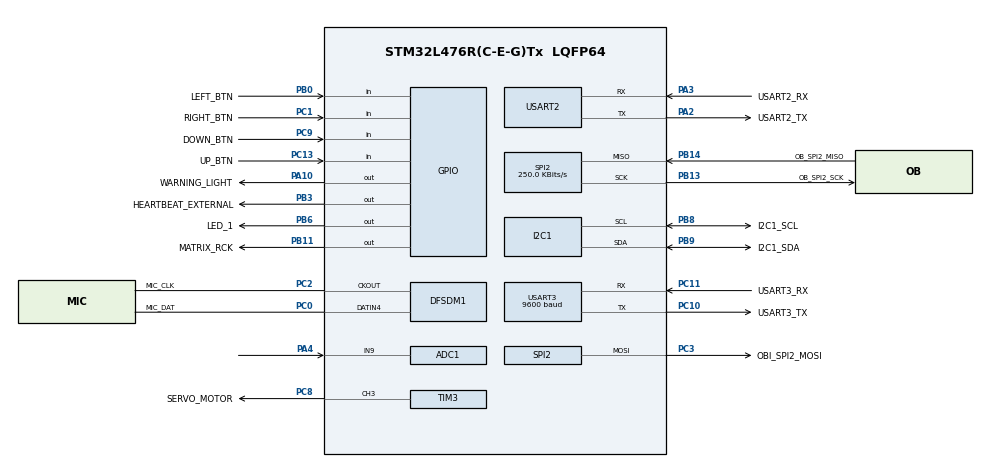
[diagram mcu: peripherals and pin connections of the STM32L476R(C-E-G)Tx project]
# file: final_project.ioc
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ADC1.Channel-0\#ChannelRegularConversion=ADC_CHANNEL_9
ADC1.NbrOfConversionFlag=1
ADC1.OffsetNumber-0\#ChannelRegularConversion=ADC_OFFSET_NONE
ADC1.Rank-0\#ChannelRegularConversion=1
ADC1.SamplingTime-0\#ChannelRegularConversion=ADC_SAMPLETIME_12CYCLES_5
ADC1.master=1
DFSDM1.Divider=2
DFSDM1.DmaMode_reg_FIL0=ENABLE
DFSDM1.DmaMode_reg_FIL1=ENABLE
DFSDM1.FastMode_reg_FIL0=ENABLE
DFSDM1.FastMode_reg_FIL1=ENABLE
DFSDM1.Filter_regChannel_FIL0=DFSDM_CHANNEL_4
DFSDM1.Filter_regChannel_FIL1=DFSDM_CHANNEL_3
DFSDM1.Fosr_FIL0=38
DFSDM1.Fosr_FIL1=38
DFSDM1.Iosr_FIL0=4
DFSDM1.Iosr_FIL1=4
DFSDM1.RightBitShift_CH3=0x08
DFSDM1.RightBitShift_CH4=0x08
DFSDM1.SincOrder_FIL0=DFSDM_FILTER_SINC4_ORDER
DFSDM1.SincOrder_FIL1=DFSDM_FILTER_SINC4_ORDER
DFSDM1.Type_spi_CH4=DFSDM_CHANNEL_SPI_FALLING
Dma.DFSDM1_FLT0.0.Direction=DMA_PERIPH_TO_MEMORY
Dma.DFSDM1_FLT0.0.Instance=DMA1_Channel4
Dma.DFSDM1_FLT0.0.MemDataAlignment=DMA_MDATAALIGN_WORD
Dma.DFSDM1_FLT0.0.MemInc=DMA_MINC_ENABLE
Dma.DFSDM1_FLT0.0.Mode=DMA_CIRCULAR
Dma.DFSDM1_FLT0.0.PeriphDataAlignment=DMA_PDATAALIGN_WORD
Dma.DFSDM1_FLT0.0.PeriphInc=DMA_PINC_DISABLE
Dma.DFSDM1_FLT0.0.Priority=DMA_PRIORITY_LOW
Dma.DFSDM1_FLT1.1.Direction=DMA_PERIPH_TO_MEMORY
Dma.DFSDM1_FLT1.1.Instance=DMA1_Channel5
Dma.DFSDM1_FLT1.1.MemDataAlignment=DMA_MDATAALIGN_WORD
Dma.DFSDM1_FLT1.1.MemInc=DMA_MINC_ENABLE
Dma.DFSDM1_FLT1.1.Mode=DMA_CIRCULAR
Dma.DFSDM1_FLT1.1.PeriphDataAlignment=DMA_PDATAALIGN_WORD
Dma.DFSDM1_FLT1.1.PeriphInc=DMA_PINC_DISABLE
Dma.DFSDM1_FLT1.1.Priority=DMA_PRIORITY_LOW
Dma.Request0=DFSDM1_FLT0
Dma.Request1=DFSDM1_FLT1
FREERTOS.Tasks01=defaultTask,24,128,StartDefaultTask,Default,NULL,Dynamic,NULL,NULL
I2C1.Timing=0x00100D14
Mcu.Family=STM32L4
Mcu.Name=STM32L476R(C-E-G)Tx
Mcu.Package=LQFP64
NVIC.DMA1_Channel4_IRQn=true\:5\:0\:false\:false\:true\:true\:false\:true\:true
NVIC.DMA1_Channel5_IRQn=true\:5\:0\:false\:false\:true\:true\:false\:true\:true
NVIC.PriorityGroup=NVIC_PRIORITYGROUP_4
PA10.GPIO_Label=WARNING_LIGHT
PA10.Signal=GPIO_Output
PA2.GPIO_Label=USART2_TX
PA2.Mode=Asynchronous
PA2.Signal=USART2_TX
PA3.GPIO_Label=USART2_RX
PA3.Mode=Asynchronous
PA3.Signal=USART2_RX
PA4.Signal=ADCx_IN9
PB0.GPIO_Label=LEFT_BTN
PB0.Signal=GPIO_Input
PB11.GPIO_Label=MATRIX_RCK
PB11.Signal=GPIO_Output
PB13.GPIO_Label=OB_SPI2_SCK
PB13.Mode=Full_Duplex_Master
PB13.Signal=SPI2_SCK
PB14.GPIO_Label=OB_SPI2_MISO
PB14.Mode=Full_Duplex_Master
PB14.Signal=SPI2_MISO
PB3\ (JTDO-TRACESWO).GPIO_Label=HEARTBEAT_EXTERNAL
PB3\ (JTDO-TRACESWO).Signal=GPIO_Output
PB6.GPIO_Label=LED_1
PB6.Signal=GPIO_Output
PB8.GPIO_Label=I2C1_SCL
PB8.Mode=I2C
PB8.Signal=I2C1_SCL
PB9.GPIO_Label=I2C1_SDA
PB9.Mode=I2C
PB9.Signal=I2C1_SDA
PC0.GPIO_Label=MIC_DAT
PC0.Signal=S_DATAIN4DFSDM1
PC1.GPIO_Label=RIGHT_BTN
PC1.Signal=GPIO_Input
PC10.GPIO_Label=USART3_TX
PC10.Mode=Asynchronous
PC10.Signal=USART3_TX
PC11.GPIO_Label=USART3_RX
PC11.Mode=Asynchronous
PC11.Signal=USART3_RX
PC13.GPIO_Label=UP_BTN
PC13.Signal=GPIO_Input
PC2.GPIO_Label=MIC_CLK
PC2.Signal=S_CKOUTDFSDM1
PC3.GPIO_Label=OBI_SPI2_MOSI
PC3.Mode=Full_Duplex_Master
PC3.Signal=SPI2_MOSI
PC8.GPIO_Label=SERVO_MOTOR
PC8.Signal=S_TIM3_CH3
PC9.GPIO_Label=DOWN_BTN
PC9.Signal=GPIO_Input
ProjectManager.HeapSize=0x200
ProjectManager.StackSize=0x400
ProjectManager.TargetToolchain=CMake
RCC.ADCFreq_Value=32000000
RCC.HSE_VALUE=8000000
RCC.HSI_VALUE=16000000
RCC.LSE_VALUE=32768
RCC.MSI_VALUE=4000000
RCC.PLLSAI1N=16
RCC.USBFreq_Value=32000000
RCC.VCOOutputFreq_Value=32000000
SH.ADCx_IN9.0=ADC1_IN9,IN9-Single-Ended
SH.S_CKOUTDFSDM1.0=DFSDM1_CKOUT,PDM_SPI_input_from_ch4_and_internal_clock
SH.S_CKOUTDFSDM1.1=DFSDM1_CKOUT,PDM_SPI_Input_from_ch34_and_Internal_Clock
SH.S_DATAIN4DFSDM1.0=DFSDM1_DATIN4,PDM_SPI_input_from_ch4_and_internal_clock
SH.S_DATAIN4DFSDM1.1=DFSDM1_DATIN4,PDM_SPI_Input_from_ch34_and_Internal_Clock
SH.S_TIM3_CH3.0=TIM3_CH3,PWM Generation3 CH3
SPI2.BaudRatePrescaler=SPI_BAUDRATEPRESCALER_16
SPI2.CalculateBaudRate=250.0 KBits/s
SPI2.DataSize=SPI_DATASIZE_8BIT
SPI2.Direction=SPI_DIRECTION_2LINES
SPI2.Mode=SPI_MODE_MASTER
SPI2.VirtualType=VM_MASTER
TIM3.Channel-PWM\ Generation3\ CH3=TIM_CHANNEL_3
TIM3.Period=19999
TIM3.Prescaler=3
USART2.VirtualMode-Asynchronous=VM_ASYNC
USART3.BaudRate=9600
USART3.VirtualMode-Asynchronous=VM_ASYNC
VP_FREERTOS_VS_CMSIS_V2.Mode=CMSIS_V2
board=custom

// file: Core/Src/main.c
/* USER CODE BEGIN Header */
/**
  ******************************************************************************
  * @file           : main.c
  * @brief          : Main program body
  ******************************************************************************
  * @attention
  *
  * Copyright (c) 2026 STMicroelectronics.
  * All rights reserved.
  *
  * This software is licensed under terms that can be found in the LICENSE file
  * in the root directory of this software component.
  * If no LICENSE file comes with this software, it is provided AS-IS.
  *
  ******************************************************************************
  */
/* USER CODE END Header */
#include "main.h"
#include "cmsis_os.h"

/* USER CODE BEGIN Includes */
#include "app.h"
/* USER CODE END Includes */

ADC_HandleTypeDef hadc1;

DFSDM_Filter_HandleTypeDef hdfsdm1_filter0;
DFSDM_Filter_HandleTypeDef hdfsdm1_filter1;
DFSDM_Channel_HandleTypeDef hdfsdm1_channel3;
DFSDM_Channel_HandleTypeDef hdfsdm1_channel4;
DMA_HandleTypeDef hdma_dfsdm1_flt0;
DMA_HandleTypeDef hdma_dfsdm1_flt1;

I2C_HandleTypeDef hi2c1;

SPI_HandleTypeDef hspi2;

TIM_HandleTypeDef htim3;

UART_HandleTypeDef huart2;
UART_HandleTypeDef huart3;

/* Definitions for defaultTask */
osThreadId_t defaultTaskHandle;
const osThreadAttr_t defaultTask_attributes = {
  .name = "defaultTask",
  .stack_size = 128 * 4,
  .priority = (osPriority_t) osPriorityNormal,
};

void SystemClock_Config(void);
static void MX_GPIO_Init(void);
static void MX_DMA_Init(void);
static void MX_ADC1_Init(void);
static void MX_DFSDM1_Init(void);
static void MX_I2C1_Init(void);
static void MX_SPI2_Init(void);
static void MX_TIM3_Init(void);
static void MX_USART2_UART_Init(void);
static void MX_USART3_UART_Init(void);
void StartDefaultTask(void *argument);

int main(void)
{

  /* MCU Configuration--------------------------------------------------------*/

  /* Reset of all peripherals, Initializes the Flash interface and the Systick. */
  HAL_Init();

  /* Configure the system clock */
  SystemClock_Config();

  /* Initialize all configured peripherals */
  MX_GPIO_Init();
  MX_DMA_Init();
  MX_ADC1_Init();
  MX_DFSDM1_Init();
  MX_I2C1_Init();
  MX_SPI2_Init();
  MX_TIM3_Init();
  MX_USART2_UART_Init();
  MX_USART3_UART_Init();
  /* USER CODE BEGIN 2 */
   // start freeRTOS app
    int err = app_main();
  UNUSED(err);

  Error_Handler(); // If app_main returns, there was an error. Handle it.

  // HD44780_Init(2); // Initialize LCD with 2 rows
  //  HD44780_Clear(); // Clear the display
  //  HD44780_Backlight(); // Turn on the backlight
  //  HD44780_SetCursor(0, 0); // Set cursor to first row, first column
  //  HD44780_PrintStr("WELCOME"); // Print string on LCD
  /* USER CODE END 2 */

  /* Init scheduler */
  osKernelInitialize();

  /* Create the thread(s) */
  /* creation of defaultTask */
  defaultTaskHandle = osThreadNew(StartDefaultTask, NULL, &defaultTask_attributes);

  /* Start scheduler */
  osKernelStart();

  /* We should never get here as control is now taken by the scheduler */

  /* Infinite loop */
  while (1)
  {

  }
}

void SystemClock_Config(void)
{
  RCC_OscInitTypeDef RCC_OscInitStruct = {0};
  RCC_ClkInitTypeDef RCC_ClkInitStruct = {0};

  /** Configure the main internal regulator output voltage
  */
  if (HAL_PWREx_ControlVoltageScaling(PWR_REGULATOR_VOLTAGE_SCALE1) != HAL_OK)
  {
    Error_Handler();
  }

  /** Initializes the RCC Oscillators according to the specified parameters
  * in the RCC_OscInitTypeDef structure.
  */
  RCC_OscInitStruct.OscillatorType = RCC_OSCILLATORTYPE_MSI;
  RCC_OscInitStruct.MSIState = RCC_MSI_ON;
  RCC_OscInitStruct.MSICalibrationValue = 0;
  RCC_OscInitStruct.MSIClockRange = RCC_MSIRANGE_6;
  RCC_OscInitStruct.PLL.PLLState = RCC_PLL_NONE;
  if (HAL_RCC_OscConfig(&RCC_OscInitStruct) != HAL_OK)
  {
    Error_Handler();
  }

  /** Initializes the CPU, AHB and APB buses clocks
  */
  RCC_ClkInitStruct.ClockType = RCC_CLOCKTYPE_HCLK|RCC_CLOCKTYPE_SYSCLK
                              |RCC_CLOCKTYPE_PCLK1|RCC_CLOCKTYPE_PCLK2;
  RCC_ClkInitStruct.SYSCLKSource = RCC_SYSCLKSOURCE_MSI;
  RCC_ClkInitStruct.AHBCLKDivider = RCC_SYSCLK_DIV1;
  RCC_ClkInitStruct.APB1CLKDivider = RCC_HCLK_DIV1;
  RCC_ClkInitStruct.APB2CLKDivider = RCC_HCLK_DIV1;

  if (HAL_RCC_ClockConfig(&RCC_ClkInitStruct, FLASH_LATENCY_0) != HAL_OK)
  {
    Error_Handler();
  }
}

static void MX_ADC1_Init(void)
{

  ADC_MultiModeTypeDef multimode = {0};
  ADC_ChannelConfTypeDef sConfig = {0};

  /** Common config
  */
  hadc1.Instance = ADC1;
  hadc1.Init.ClockPrescaler = ADC_CLOCK_ASYNC_DIV1;
  hadc1.Init.Resolution = ADC_RESOLUTION_12B;
  hadc1.Init.DataAlign = ADC_DATAALIGN_RIGHT;
  hadc1.Init.ScanConvMode = ADC_SCAN_DISABLE;
  hadc1.Init.EOCSelection = ADC_EOC_SINGLE_CONV;
  hadc1.Init.LowPowerAutoWait = DISABLE;
  hadc1.Init.ContinuousConvMode = DISABLE;
  hadc1.Init.NbrOfConversion = 1;
  hadc1.Init.DiscontinuousConvMode = DISABLE;
  hadc1.Init.ExternalTrigConv = ADC_SOFTWARE_START;
  hadc1.Init.ExternalTrigConvEdge = ADC_EXTERNALTRIGCONVEDGE_NONE;
  hadc1.Init.DMAContinuousRequests = DISABLE;
  hadc1.Init.Overrun = ADC_OVR_DATA_PRESERVED;
  hadc1.Init.OversamplingMode = DISABLE;
  if (HAL_ADC_Init(&hadc1) != HAL_OK)
  {
    Error_Handler();
  }

  /** Configure the ADC multi-mode
  */
  multimode.Mode = ADC_MODE_INDEPENDENT;
  if (HAL_ADCEx_MultiModeConfigChannel(&hadc1, &multimode) != HAL_OK)
  {
    Error_Handler();
  }

  /** Configure Regular Channel
  */
  sConfig.Channel = ADC_CHANNEL_9;
  sConfig.Rank = ADC_REGULAR_RANK_1;
  sConfig.SamplingTime = ADC_SAMPLETIME_12CYCLES_5;
  sConfig.SingleDiff = ADC_SINGLE_ENDED;
  sConfig.OffsetNumber = ADC_OFFSET_NONE;
  sConfig.Offset = 0;
  if (HAL_ADC_ConfigChannel(&hadc1, &sConfig) != HAL_OK)
  {
    Error_Handler();
  }

}

static void MX_DFSDM1_Init(void)
{

  hdfsdm1_filter0.Instance = DFSDM1_Filter0;
  hdfsdm1_filter0.Init.RegularParam.Trigger = DFSDM_FILTER_SW_TRIGGER;
  hdfsdm1_filter0.Init.RegularParam.FastMode = ENABLE;
  hdfsdm1_filter0.Init.RegularParam.DmaMode = ENABLE;
  hdfsdm1_filter0.Init.FilterParam.SincOrder = DFSDM_FILTER_SINC4_ORDER;
  hdfsdm1_filter0.Init.FilterParam.Oversampling = 38;
  hdfsdm1_filter0.Init.FilterParam.IntOversampling = 4;
  if (HAL_DFSDM_FilterInit(&hdfsdm1_filter0) != HAL_OK)
  {
    Error_Handler();
  }
  hdfsdm1_filter1.Instance = DFSDM1_Filter1;
  hdfsdm1_filter1.Init.RegularParam.Trigger = DFSDM_FILTER_SW_TRIGGER;
  hdfsdm1_filter1.Init.RegularParam.FastMode = ENABLE;
  hdfsdm1_filter1.Init.RegularParam.DmaMode = ENABLE;
  hdfsdm1_filter1.Init.FilterParam.SincOrder = DFSDM_FILTER_SINC4_ORDER;
  hdfsdm1_filter1.Init.FilterParam.Oversampling = 38;
  hdfsdm1_filter1.Init.FilterParam.IntOversampling = 4;
  if (HAL_DFSDM_FilterInit(&hdfsdm1_filter1) != HAL_OK)
  {
    Error_Handler();
  }
  hdfsdm1_channel3.Instance = DFSDM1_Channel3;
  hdfsdm1_channel3.Init.OutputClock.Activation = ENABLE;
  hdfsdm1_channel3.Init.OutputClock.Selection = DFSDM_CHANNEL_OUTPUT_CLOCK_SYSTEM;
  hdfsdm1_channel3.Init.OutputClock.Divider = 2;
  hdfsdm1_channel3.Init.Input.Multiplexer = DFSDM_CHANNEL_EXTERNAL_INPUTS;
  hdfsdm1_channel3.Init.Input.DataPacking = DFSDM_CHANNEL_STANDARD_MODE;
  hdfsdm1_channel3.Init.Input.Pins = DFSDM_CHANNEL_FOLLOWING_CHANNEL_PINS;
  hdfsdm1_channel3.Init.SerialInterface.Type = DFSDM_CHANNEL_SPI_RISING;
  hdfsdm1_channel3.Init.SerialInterface.SpiClock = DFSDM_CHANNEL_SPI_CLOCK_INTERNAL;
  hdfsdm1_channel3.Init.Awd.FilterOrder = DFSDM_CHANNEL_FASTSINC_ORDER;
  hdfsdm1_channel3.Init.Awd.Oversampling = 1;
  hdfsdm1_channel3.Init.Offset = 0;
  hdfsdm1_channel3.Init.RightBitShift = 0x08;
  if (HAL_DFSDM_ChannelInit(&hdfsdm1_channel3) != HAL_OK)
  {
    Error_Handler();
  }
  hdfsdm1_channel4.Instance = DFSDM1_Channel4;
  hdfsdm1_channel4.Init.OutputClock.Activation = ENABLE;
  hdfsdm1_channel4.Init.OutputClock.Selection = DFSDM_CHANNEL_OUTPUT_CLOCK_SYSTEM;
  hdfsdm1_channel4.Init.OutputClock.Divider = 2;
  hdfsdm1_channel4.Init.Input.Multiplexer = DFSDM_CHANNEL_EXTERNAL_INPUTS;
  hdfsdm1_channel4.Init.Input.DataPacking = DFSDM_CHANNEL_STANDARD_MODE;
  hdfsdm1_channel4.Init.Input.Pins = DFSDM_CHANNEL_SAME_CHANNEL_PINS;
  hdfsdm1_channel4.Init.SerialInterface.Type = DFSDM_CHANNEL_SPI_FALLING;
  hdfsdm1_channel4.Init.SerialInterface.SpiClock = DFSDM_CHANNEL_SPI_CLOCK_INTERNAL;
  hdfsdm1_channel4.Init.Awd.FilterOrder = DFSDM_CHANNEL_FASTSINC_ORDER;
  hdfsdm1_channel4.Init.Awd.Oversampling = 1;
  hdfsdm1_channel4.Init.Offset = 0;
  hdfsdm1_channel4.Init.RightBitShift = 0x08;
  if (HAL_DFSDM_ChannelInit(&hdfsdm1_channel4) != HAL_OK)
  {
    Error_Handler();
  }
  if (HAL_DFSDM_FilterConfigRegChannel(&hdfsdm1_filter0, DFSDM_CHANNEL_4, DFSDM_CONTINUOUS_CONV_ON) != HAL_OK)
  {
    Error_Handler();
  }
  if (HAL_DFSDM_FilterConfigRegChannel(&hdfsdm1_filter1, DFSDM_CHANNEL_3, DFSDM_CONTINUOUS_CONV_ON) != HAL_OK)
  {
    Error_Handler();
  }

}

static void MX_I2C1_Init(void)
{

  hi2c1.Instance = I2C1;
  hi2c1.Init.Timing = 0x00100D14;
  hi2c1.Init.OwnAddress1 = 0;
  hi2c1.Init.AddressingMode = I2C_ADDRESSINGMODE_7BIT;
  hi2c1.Init.DualAddressMode = I2C_DUALADDRESS_DISABLE;
  hi2c1.Init.OwnAddress2 = 0;
  hi2c1.Init.OwnAddress2Masks = I2C_OA2_NOMASK;
  hi2c1.Init.GeneralCallMode = I2C_GENERALCALL_DISABLE;
  hi2c1.Init.NoStretchMode = I2C_NOSTRETCH_DISABLE;
  if (HAL_I2C_Init(&hi2c1) != HAL_OK)
  {
    Error_Handler();
  }

  /** Configure Analogue filter
  */
  if (HAL_I2CEx_ConfigAnalogFilter(&hi2c1, I2C_ANALOGFILTER_ENABLE) != HAL_OK)
  {
    Error_Handler();
  }

  /** Configure Digital filter
  */
  if (HAL_I2CEx_ConfigDigitalFilter(&hi2c1, 0) != HAL_OK)
  {
    Error_Handler();
  }

}

static void MX_SPI2_Init(void)
{

  /* SPI2 parameter configuration*/
  hspi2.Instance = SPI2;
  hspi2.Init.Mode = SPI_MODE_MASTER;
  hspi2.Init.Direction = SPI_DIRECTION_2LINES;
  hspi2.Init.DataSize = SPI_DATASIZE_8BIT;
  hspi2.Init.CLKPolarity = SPI_POLARITY_LOW;
  hspi2.Init.CLKPhase = SPI_PHASE_1EDGE;
  hspi2.Init.NSS = SPI_NSS_SOFT;
  hspi2.Init.BaudRatePrescaler = SPI_BAUDRATEPRESCALER_16;
  hspi2.Init.FirstBit = SPI_FIRSTBIT_MSB;
  hspi2.Init.TIMode = SPI_TIMODE_DISABLE;
  hspi2.Init.CRCCalculation = SPI_CRCCALCULATION_DISABLE;
  hspi2.Init.CRCPolynomial = 7;
  hspi2.Init.CRCLength = SPI_CRC_LENGTH_DATASIZE;
  hspi2.Init.NSSPMode = SPI_NSS_PULSE_ENABLE;
  if (HAL_SPI_Init(&hspi2) != HAL_OK)
  {
    Error_Handler();
  }

}

static void MX_TIM3_Init(void)
{

  TIM_MasterConfigTypeDef sMasterConfig = {0};
  TIM_OC_InitTypeDef sConfigOC = {0};

  htim3.Instance = TIM3;
  htim3.Init.Prescaler = 3;
  htim3.Init.CounterMode = TIM_COUNTERMODE_UP;
  htim3.Init.Period = 19999;
  htim3.Init.ClockDivision = TIM_CLOCKDIVISION_DIV1;
  htim3.Init.AutoReloadPreload = TIM_AUTORELOAD_PRELOAD_DISABLE;
  if (HAL_TIM_PWM_Init(&htim3) != HAL_OK)
  {
    Error_Handler();
  }
  sMasterConfig.MasterOutputTrigger = TIM_TRGO_RESET;
  sMasterConfig.MasterSlaveMode = TIM_MASTERSLAVEMODE_DISABLE;
  if (HAL_TIMEx_MasterConfigSynchronization(&htim3, &sMasterConfig) != HAL_OK)
  {
    Error_Handler();
  }
  sConfigOC.OCMode = TIM_OCMODE_PWM1;
  sConfigOC.Pulse = 0;
  sConfigOC.OCPolarity = TIM_OCPOLARITY_HIGH;
  sConfigOC.OCFastMode = TIM_OCFAST_DISABLE;
  if (HAL_TIM_PWM_ConfigChannel(&htim3, &sConfigOC, TIM_CHANNEL_3) != HAL_OK)
  {
    Error_Handler();
  }
  HAL_TIM_MspPostInit(&htim3);

}

static void MX_USART2_UART_Init(void)
{

  huart2.Instance = USART2;
  huart2.Init.BaudRate = 115200;
  huart2.Init.WordLength = UART_WORDLENGTH_8B;
  huart2.Init.StopBits = UART_STOPBITS_1;
  huart2.Init.Parity = UART_PARITY_NONE;
  huart2.Init.Mode = UART_MODE_TX_RX;
  huart2.Init.HwFlowCtl = UART_HWCONTROL_NONE;
  huart2.Init.OverSampling = UART_OVERSAMPLING_16;
  huart2.Init.OneBitSampling = UART_ONE_BIT_SAMPLE_DISABLE;
  huart2.AdvancedInit.AdvFeatureInit = UART_ADVFEATURE_NO_INIT;
  if (HAL_UART_Init(&huart2) != HAL_OK)
  {
    Error_Handler();
  }

}

static void MX_USART3_UART_Init(void)
{

  huart3.Instance = USART3;
  huart3.Init.BaudRate = 9600;
  huart3.Init.WordLength = UART_WORDLENGTH_8B;
  huart3.Init.StopBits = UART_STOPBITS_1;
  huart3.Init.Parity = UART_PARITY_NONE;
  huart3.Init.Mode = UART_MODE_TX_RX;
  huart3.Init.HwFlowCtl = UART_HWCONTROL_NONE;
  huart3.Init.OverSampling = UART_OVERSAMPLING_16;
  huart3.Init.OneBitSampling = UART_ONE_BIT_SAMPLE_DISABLE;
  huart3.AdvancedInit.AdvFeatureInit = UART_ADVFEATURE_NO_INIT;
  if (HAL_UART_Init(&huart3) != HAL_OK)
  {
    Error_Handler();
  }

}

static void MX_DMA_Init(void)
{

  /* DMA controller clock enable */
  __HAL_RCC_DMA1_CLK_ENABLE();

  /* DMA interrupt init */
  /* DMA1_Channel4_IRQn interrupt configuration */
  HAL_NVIC_SetPriority(DMA1_Channel4_IRQn, 5, 0);
  HAL_NVIC_EnableIRQ(DMA1_Channel4_IRQn);
  /* DMA1_Channel5_IRQn interrupt configuration */
  HAL_NVIC_SetPriority(DMA1_Channel5_IRQn, 5, 0);
  HAL_NVIC_EnableIRQ(DMA1_Channel5_IRQn);

}

static void MX_GPIO_Init(void)
{
  GPIO_InitTypeDef GPIO_InitStruct = {0};

  /* GPIO Ports Clock Enable */
  __HAL_RCC_GPIOC_CLK_ENABLE();
  __HAL_RCC_GPIOA_CLK_ENABLE();
  __HAL_RCC_GPIOB_CLK_ENABLE();

  /*Configure GPIO pin Output Level */
  HAL_GPIO_WritePin(GPIOB, MATRIX_RCK_Pin|HEARTBEAT_EXTERNAL_Pin|LED_1_Pin, GPIO_PIN_RESET);

  /*Configure GPIO pin Output Level */
  HAL_GPIO_WritePin(WARNING_LIGHT_GPIO_Port, WARNING_LIGHT_Pin, GPIO_PIN_RESET);

  /*Configure GPIO pins : UP_BTN_Pin RIGHT_BTN_Pin DOWN_BTN_Pin */
  GPIO_InitStruct.Pin = UP_BTN_Pin|RIGHT_BTN_Pin|DOWN_BTN_Pin;
  GPIO_InitStruct.Mode = GPIO_MODE_INPUT;
  GPIO_InitStruct.Pull = GPIO_NOPULL;
  HAL_GPIO_Init(GPIOC, &GPIO_InitStruct);

  /*Configure GPIO pin : LEFT_BTN_Pin */
  GPIO_InitStruct.Pin = LEFT_BTN_Pin;
  GPIO_InitStruct.Mode = GPIO_MODE_INPUT;
  GPIO_InitStruct.Pull = GPIO_NOPULL;
  HAL_GPIO_Init(LEFT_BTN_GPIO_Port, &GPIO_InitStruct);

  /*Configure GPIO pins : MATRIX_RCK_Pin HEARTBEAT_EXTERNAL_Pin LED_1_Pin */
  GPIO_InitStruct.Pin = MATRIX_RCK_Pin|HEARTBEAT_EXTERNAL_Pin|LED_1_Pin;
  GPIO_InitStruct.Mode = GPIO_MODE_OUTPUT_PP;
  GPIO_InitStruct.Pull = GPIO_NOPULL;
  GPIO_InitStruct.Speed = GPIO_SPEED_FREQ_LOW;
  HAL_GPIO_Init(GPIOB, &GPIO_InitStruct);

  /*Configure GPIO pin : WARNING_LIGHT_Pin */
  GPIO_InitStruct.Pin = WARNING_LIGHT_Pin;
  GPIO_InitStruct.Mode = GPIO_MODE_OUTPUT_PP;
  GPIO_InitStruct.Pull = GPIO_NOPULL;
  GPIO_InitStruct.Speed = GPIO_SPEED_FREQ_LOW;
  HAL_GPIO_Init(WARNING_LIGHT_GPIO_Port, &GPIO_InitStruct);

}

void StartDefaultTask(void *argument)
{
  for(;;)
  {
    osDelay(1);
  }
}

void Error_Handler(void)
{
  __disable_irq();
  while (1)
  {
  }
}
